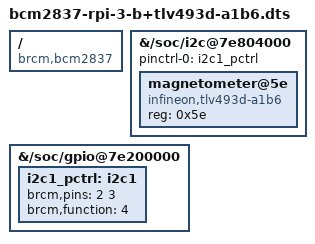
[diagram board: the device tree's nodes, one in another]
/*
 * Copyright (c) 2017 Andreas Färber
 *
 * SPDX-License-Identifier: GPL-2.0+ OR MIT
 */

/dts-v1/;
/plugin/;

/ {
	compatible = "brcm,bcm2837";

	#address-cells = <1>;
	#size-cells = <0>;

	fragment@0 {
		reg = <0>;

		target-path = "/soc/i2c@7e804000";

		__overlay__ {
			pinctrl-names = "default";
			pinctrl-0 = <&i2c1_pctrl>;

			#address-cells = <1>;
			#size-cells = <0>;

			magnetometer@5e {
				compatible = "infineon,tlv493d-a1b6";
				reg = <0x5e>;
			};
		};
	};

	fragment@1 {
		reg = <1>;

		target-path = "/soc/gpio@7e200000";

		__overlay__ {
			i2c1_pctrl: i2c1 {
				brcm,pins = <2 3>;
				brcm,function = <4>;
			};
		};
	};
};
